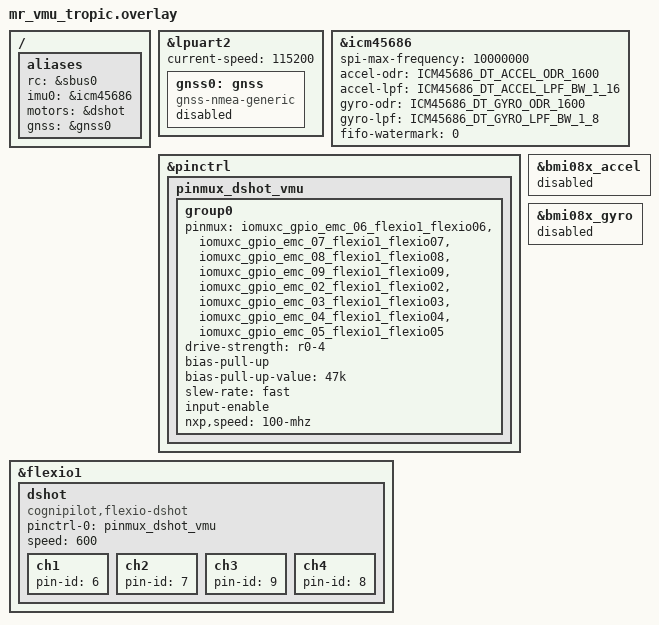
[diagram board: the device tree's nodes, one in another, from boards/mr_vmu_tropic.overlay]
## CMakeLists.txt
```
cmake_minimum_required(VERSION 3.20.0)

list(APPEND DTS_ROOT ${CMAKE_CURRENT_SOURCE_DIR})

get_filename_component(REPO_ROOT ${CMAKE_CURRENT_SOURCE_DIR} DIRECTORY)
get_filename_component(WORKSPACE_ROOT ${REPO_ROOT} DIRECTORY)
set(ZEPHYR_MODULES
  ${WORKSPACE_ROOT}/modules/hal/cmsis
  ${WORKSPACE_ROOT}/modules/hal/cmsis_6
  ${WORKSPACE_ROOT}/modules/hal/nxp
  ${WORKSPACE_ROOT}/modules/lib/cmsis-dsp
  ${WORKSPACE_ROOT}/modules/lib/zenoh-pico
  ${WORKSPACE_ROOT}/modules/lib/zros
  ${WORKSPACE_ROOT}/modules/lib/zephyr_boards
)

find_package(Zephyr REQUIRED HINTS $ENV{ZEPHYR_BASE})
project(rdd2 LANGUAGES C)

set(RDD2_FLATBUFFER_SCHEMA_DIR
  ${WORKSPACE_ROOT}/modules/lib/synapse_msgs_fbs/fbs/synapse
)
set(RDD2_FLATBUFFER_SCHEMA
  ${RDD2_FLATBUFFER_SCHEMA_DIR}/synapse_topics.fbs
)
set(RDD2_FLATBUFFER_LOG_SCHEMA
  ${RDD2_FLATBUFFER_SCHEMA_DIR}/synapse_log.fbs
)
set(RDD2_FLATBUFFER_SIL_SCHEMA
  ${RDD2_FLATBUFFER_SCHEMA_DIR}/synapse_sil.fbs
)
set(RDD2_FLATBUFFER_GENERATED_DIR
  ${CMAKE_CURRENT_BINARY_DIR}/generated/flatbuffers
)
set(RDD2_FLATBUFFER_STAMP
  ${RDD2_FLATBUFFER_GENERATED_DIR}/.flatcc.stamp
)
set(RDD2_FLATBUFFER_BFBS_STAMP
  ${RDD2_FLATBUFFER_GENERATED_DIR}/.bfbs.stamp
)
set(RDD2_FLATBUFFER_STAGE_STAMP
  ${RDD2_FLATBUFFER_GENERATED_DIR}/.schema-copy.stamp
)
option(RDD2_FLATBUFFER_CODEGEN
  "Generate FlatBuffer C headers and binary schemas into the build tree when flatcc is available"
  ON
)

find_program(RDD2_FLATCC_EXECUTABLE NAMES flatcc)

if(RDD2_FLATCC_EXECUTABLE)
  get_filename_component(RDD2_FLATCC_REALPATH ${RDD2_FLATCC_EXECUTABLE} REALPATH)
  get_filename_component(RDD2_FLATCC_BIN_DIR ${RDD2_FLATCC_REALPATH} DIRECTORY)
  get_filename_component(RDD2_FLATCC_PREFIX ${RDD2_FLATCC_BIN_DIR} DIRECTORY)
endif()

find_path(RDD2_FLATCC_INCLUDE_DIR
  NAMES flatcc/flatcc_builder.h
  HINTS ${RDD2_FLATCC_PREFIX}/include
)

if(NOT EXISTS ${RDD2_FLATBUFFER_SCHEMA})
  message(FATAL_ERROR
    "Missing FlatBuffer topic schema: ${RDD2_FLATBUFFER_SCHEMA}. "
    "Run west update to fetch modules/lib/synapse_msgs_fbs."
  )
endif()

if(NOT EXISTS ${RDD2_FLATBUFFER_LOG_SCHEMA})
  message(FATAL_ERROR
    "Missing FlatBuffer log schema: ${RDD2_FLATBUFFER_LOG_SCHEMA}. "
    "Run west update to fetch modules/lib/synapse_msgs_fbs."
  )
endif()

if(NOT EXISTS ${RDD2_FLATBUFFER_SIL_SCHEMA})
  message(FATAL_ERROR
    "Missing FlatBuffer SITL schema: ${RDD2_FLATBUFFER_SIL_SCHEMA}. "
    "Run west update to fetch modules/lib/synapse_msgs_fbs."
  )
endif()

if(RDD2_FLATBUFFER_CODEGEN AND RDD2_FLATCC_EXECUTABLE)
  add_custom_command(
    OUTPUT ${RDD2_FLATBUFFER_STAGE_STAMP}
    COMMAND ${CMAKE_COMMAND} -E make_directory ${RDD2_FLATBUFFER_GENERATED_DIR}
    COMMAND ${CMAKE_COMMAND} -E copy_if_different
            ${RDD2_FLATBUFFER_SCHEMA}
            ${RDD2_FLATBUFFER_GENERATED_DIR}/synapse_topics.fbs
    COMMAND ${CMAKE_COMMAND} -E copy_if_different
            ${RDD2_FLATBUFFER_LOG_SCHEMA}
            ${RDD2_FLATBUFFER_GENERATED_DIR}/synapse_log.fbs
    COMMAND ${CMAKE_COMMAND} -E copy_if_different
            ${RDD2_FLATBUFFER_SIL_SCHEMA}
            ${RDD2_FLATBUFFER_GENERATED_DIR}/synapse_sil.fbs
    COMMAND ${CMAKE_COMMAND} -E touch ${RDD2_FLATBUFFER_STAGE_STAMP}
    DEPENDS
      ${RDD2_FLATBUFFER_SCHEMA}
      ${RDD2_FLATBUFFER_LOG_SCHEMA}
      ${RDD2_FLATBUFFER_SIL_SCHEMA}
    COMMENT "Staging FlatBuffer schemas into ${RDD2_FLATBUFFER_GENERATED_DIR}"
    VERBATIM
  )

  add_custom_command(
    OUTPUT ${RDD2_FLATBUFFER_STAMP}
    COMMAND ${RDD2_FLATCC_EXECUTABLE}
            -a
            -I${RDD2_FLATBUFFER_SCHEMA_DIR}
            -o${RDD2_FLATBUFFER_GENERATED_DIR}
            ${RDD2_FLATBUFFER_SCHEMA}
    COMMAND ${RDD2_FLATCC_EXECUTABLE}
            -a
            -I${RDD2_FLATBUFFER_SCHEMA_DIR}
            -o${RDD2_FLATBUFFER_GENERATED_DIR}
            ${RDD2_FLATBUFFER_LOG_SCHEMA}
    COMMAND ${RDD2_FLATCC_EXECUTABLE}
            -a
            -I${RDD2_FLATBUFFER_SCHEMA_DIR}
            -o${RDD2_FLATBUFFER_GENERATED_DIR}
            ${RDD2_FLATBUFFER_SIL_SCHEMA}
    COMMAND ${CMAKE_COMMAND} -E touch ${RDD2_FLATBUFFER_STAMP}
    DEPENDS
      ${RDD2_FLATBUFFER_STAGE_STAMP}
      ${RDD2_FLATBUFFER_SCHEMA}
      ${RDD2_FLATBUFFER_LOG_SCHEMA}
      ${RDD2_FLATBUFFER_SIL_SCHEMA}
    COMMENT "Generating FlatBuffer headers into ${RDD2_FLATBUFFER_GENERATED_DIR}"
    VERBATIM
  )

  add_custom_target(rdd2_flatbuffer_codegen DEPENDS ${RDD2_FLATBUFFER_STAMP})
  add_custom_command(
    OUTPUT ${RDD2_FLATBUFFER_BFBS_STAMP}
    COMMAND ${RDD2_FLATCC_EXECUTABLE}
            --schema
            -I${RDD2_FLATBUFFER_SCHEMA_DIR}
            -o${RDD2_FLATBUFFER_GENERATED_DIR}
            ${RDD2_FLATBUFFER_SCHEMA}
    COMMAND ${RDD2_FLATCC_EXECUTABLE}
            --schema
            -I${RDD2_FLATBUFFER_SCHEMA_DIR}
            -o${RDD2_FLATBUFFER_GENERATED_DIR}
            ${RDD2_FLATBUFFER_LOG_SCHEMA}
    COMMAND ${RDD2_FLATCC_EXECUTABLE}
            --schema
            -I${RDD2_FLATBUFFER_SCHEMA_DIR}
            -o${RDD2_FLATBUFFER_GENERATED_DIR}
            ${RDD2_FLATBUFFER_SIL_SCHEMA}
    COMMAND ${CMAKE_COMMAND} -E touch ${RDD2_FLATBUFFER_BFBS_STAMP}
    DEPENDS
      ${RDD2_FLATBUFFER_STAGE_STAMP}
      ${RDD2_FLATBUFFER_SCHEMA}
      ${RDD2_FLATBUFFER_LOG_SCHEMA}
      ${RDD2_FLATBUFFER_SIL_SCHEMA}
    COMMENT "Generating FlatBuffer binary schemas into ${RDD2_FLATBUFFER_GENERATED_DIR}"
    VERBATIM
  )

  add_custom_target(rdd2_flatbuffer_schema_codegen
    DEPENDS ${RDD2_FLATBUFFER_BFBS_STAMP}
  )
elseif(RDD2_FLATBUFFER_CODEGEN)
  message(FATAL_ERROR
    "flatcc is required to build RDD2 because the firmware now compiles "
    "against generated FlatBuffer headers."
  )
endif()

if(NOT RDD2_FLATCC_INCLUDE_DIR)
  message(FATAL_ERROR
    "Missing flatcc headers. Expected flatcc/flatcc_builder.h near ${RDD2_FLATCC_EXECUTABLE}."
  )
endif()

if(TARGET rdd2_flatbuffer_codegen)
  add_dependencies(app rdd2_flatbuffer_codegen)
endif()

if(TARGET rdd2_flatbuffer_schema_codegen)
  add_dependencies(app rdd2_flatbuffer_schema_codegen)
endif()

target_include_directories(app PRIVATE
  include
  ${RDD2_FLATBUFFER_GENERATED_DIR}
  ${RDD2_FLATCC_INCLUDE_DIR}
  ${ZEPHYR_BASE}/../modules/hal/nxp/mcux/mcux-sdk-ng/drivers/flexio
)

add_subdirectory(src)
add_subdirectory(subsys)
add_subdirectory(drivers)
```

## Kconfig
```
source "Kconfig.zephyr"

menu "RDD2"

rsource "subsys/Kconfig"
rsource "drivers/Kconfig"

endmenu
```

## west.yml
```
# SPDX-License-Identifier: Apache-2.0

manifest:
  self:
    path: cerebri/rdd2
    west-commands: rdd2/scripts/west-commands.yml

  remotes:
    - name: zephyrproject-rtos
      url-base: https://github.com/zephyrproject-rtos
    - name: cognipilot
      url-base: https://github.com/CogniPilot

  projects:
    - name: zephyr
      remote: cognipilot
      revision: c908d12ebc2baa679d0f5b8e31eeb459ea93caff # cerebri2 4/14/26
      path: zephyr
      west-commands: scripts/west-commands.yml
    - name: cmsis
      remote: zephyrproject-rtos
      revision: 512cc7e895e8491696b61f7ba8066b4a182569b8 # loaded in ~/cognipilot/ws/modules/hal/cmsis
      path: modules/hal/cmsis
    - name: cmsis-dsp
      remote: zephyrproject-rtos
      revision: 97512610ec92058f0119450b9e743eeb7e95b5c8 # loaded in ~/cognipilot/ws/modules/lib/cmsis-dsp
      path: modules/lib/cmsis-dsp
    - name: cmsis_6
      remote: zephyrproject-rtos
      revision: 30a859f44ef8ab4dc8f84b03ed586fd16ccf9d74 # loaded in ~/cognipilot/ws/modules/hal/cmsis_6
      path: modules/hal/cmsis_6
    - name: hal_nxp
      remote: cognipilot
      revision: cf8f1631e862528ee044850bcc70273975b90771 # loaded in ~/cognipilot/ws/modules/hal/nxp
      path: modules/hal/nxp
    - name: zros
      remote: cognipilot
      revision: 959bce412d6e12b3a49fb8b55c219affcf7f6d0e # cerebri2 4/14/26
      path: modules/lib/zros
    - name: zenoh-pico
      url: https://github.com/cognipilot/zenoh-pico.git
      revision: 3c203551f37c5ad0b6f5471a8c344d376c04127b  # cerebri2 4/14/26
      path: modules/lib/zenoh-pico
    - name: zephyr_boards
      remote: cognipilot
      revision: d006ec84e621ee33f43c233a96380c8c3f6470eb # cerebri2 4/14/26
      path: modules/lib/zephyr_boards
    - name: synapse_msgs_fbs
      url: https://github.com/CogniPilot/synapse_msgs_fbs.git
      revision: 764acec47c44f8b9363e2a704cb4b8043b127d88 # cerebri2 4/14/26
      path: modules/lib/synapse_msgs_fbs
```

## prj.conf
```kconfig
CONFIG_MAIN_STACK_SIZE=6144
CONFIG_MAIN_THREAD_PRIORITY=2
CONFIG_SYSTEM_WORKQUEUE_STACK_SIZE=2048
CONFIG_THREAD_NAME=y
CONFIG_THREAD_MONITOR=y
CONFIG_THREAD_STACK_INFO=y
CONFIG_INIT_STACKS=y
CONFIG_THREAD_RUNTIME_STATS=y

CONFIG_ASSERT=y
CONFIG_FPU=y
CONFIG_POLL=y
CONFIG_HEAP_MEM_POOL_SIZE=32768
CONFIG_ZROS=y
CONFIG_ZROS_SHELL=y

CONFIG_LOG=y
CONFIG_LOG_MODE_IMMEDIATE=y
CONFIG_LOG_DEFAULT_LEVEL=2
CONFIG_LOG_CMDS=y
CONFIG_LOG_BACKEND_UART=n
CONFIG_LOG_PRINTK=n

CONFIG_CONSOLE=y
CONFIG_SERIAL=y
CONFIG_UART_ASYNC_API=y
CONFIG_UART_INTERRUPT_DRIVEN=y

CONFIG_SHELL=y
CONFIG_SHELL_BACKEND_SERIAL=y
CONFIG_SHELL_LOG_BACKEND=y
CONFIG_SHELL_PROMPT_UART="rdd2:~$ "
CONFIG_SHELL_STACK_SIZE=6144
CONFIG_DEVICE_SHELL=y
CONFIG_KERNEL_SHELL=y
```

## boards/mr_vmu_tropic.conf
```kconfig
CONFIG_INPUT=y
CONFIG_INPUT_MODE_SYNCHRONOUS=y
CONFIG_INPUT_SHELL=y
CONFIG_INPUT_EVENT_DUMP=y
CONFIG_INPUT_CRSF=y
CONFIG_INPUT_CRSF_SEND_SYNC=y
CONFIG_INPUT_CRSF_REPORT_FILTER=1
CONFIG_INPUT_CRSF_THREAD_PRIORITY=1
CONFIG_INPUT_CRSF_THREAD_STACK_SIZE=2048
CONFIG_INPUT_CRSF_USE_DTCM_FOR_DMA_BUFFER=y
CONFIG_CODE_DATA_RELOCATION=y
CONFIG_POSIX_API=y
CONFIG_MAX_PTHREAD_MUTEX_COUNT=16
CONFIG_MAX_PTHREAD_COND_COUNT=8

CONFIG_DSP=y
CONFIG_DSP_BACKEND_CMSIS=y
CONFIG_CMSIS_DSP=y

CONFIG_SENSOR=y
CONFIG_SENSOR_ASYNC_API=y
CONFIG_SENSOR_SHELL=y
CONFIG_ICM45686_STREAM=y
CONFIG_PINCTRL=y
CONFIG_CLOCK_CONTROL=y
CONFIG_DMA=y
CONFIG_MDIO=y
CONFIG_MDIO_SHELL=y
CONFIG_NETWORKING=y
CONFIG_NET_IPV4=y
CONFIG_NET_IPV6=n
CONFIG_NET_UDP=y
CONFIG_NET_CONFIG_SETTINGS=y
CONFIG_NET_CONFIG_NEED_IPV4=y
CONFIG_NET_CONFIG_INIT_TIMEOUT=0
CONFIG_NET_CONFIG_MY_IPV4_ADDR="192.0.2.1"
CONFIG_NET_CONFIG_MY_IPV4_NETMASK="255.255.255.0"
CONFIG_NET_CONFIG_PEER_IPV4_ADDR="192.0.2.2"
CONFIG_NET_SHELL=y
CONFIG_NET_STATISTICS=y
CONFIG_NET_STATISTICS_PER_INTERFACE=y
CONFIG_NET_STATISTICS_USER_API=y
CONFIG_NET_STATISTICS_IPV4=y
CONFIG_NET_STATISTICS_ICMP=y
CONFIG_NET_STATISTICS_UDP=y
CONFIG_NET_STATISTICS_ETHERNET=y
CONFIG_ZENOH_PICO_SHELL=y
CONFIG_ZENOH_PICO_SHELL_MODE="client"
CONFIG_ZENOH_PICO_SHELL_CONNECT_LOCATOR="udp/192.0.2.2:7447"
CONFIG_ZENOH_PICO_SHELL_SUB_KEYEXPR="**"
CONFIG_ZENOH_PICO_SHELL_THREAD_PRIORITY=5
CONFIG_ZENOH_PICO_SHELL_THREAD_STACK_SIZE=4096
CONFIG_ZENOH_PICO_SHELL_RETRY_MS=1000
CONFIG_ZENOH_PICO_SHELL_MAX_PAYLOAD=512
CONFIG_ZENOH_PICO_SHELL_MAX_KEYEXPR=96
CONFIG_SPI_NXP_LPSPI_DMA=n
CONFIG_GNSS=y
```

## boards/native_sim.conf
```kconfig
CONFIG_NATIVE_SIM_SLOWDOWN_TO_REAL_TIME=y
CONFIG_REQUIRES_FULL_LIBC=y

CONFIG_INPUT=y
CONFIG_INPUT_MODE_SYNCHRONOUS=y
CONFIG_SENSOR=y

CONFIG_UART_NATIVE_PTY=y
CONFIG_UART_NATIVE_PTY_0_ON_STDINOUT=y
```

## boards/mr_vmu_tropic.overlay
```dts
/* SPDX-License-Identifier: Apache-2.0 */

#include <zephyr/dt-bindings/sensor/icm45686.h>

/ {
	aliases {
		rc = &sbus0;
		imu0 = &icm45686;
		motors = &dshot;
		gnss = &gnss0;
	};
};

&lpuart2 {
	status = "okay";
	current-speed = <115200>;

	gnss0: gnss {
		status = "disabled";
		compatible = "gnss-nmea-generic";
	};
};

&icm45686 {
	spi-max-frequency = <10000000>;
	/*
	 * Pace the rate loop directly from the IMU data-ready interrupt at
	 * 1600 Hz. Keep the filter settings conservative enough to cut motor
	 * vibration without adding extra control-path threading.
	 */
	accel-odr = <ICM45686_DT_ACCEL_ODR_1600>;
	accel-lpf = <ICM45686_DT_ACCEL_LPF_BW_1_16>;
	gyro-odr = <ICM45686_DT_GYRO_ODR_1600>;
	gyro-lpf = <ICM45686_DT_GYRO_LPF_BW_1_8>;
	fifo-watermark = <0>;
};

&pinctrl {
	pinmux_dshot_vmu: pinmux_dshot_vmu {
		group0 {
			pinmux = <&iomuxc_gpio_emc_06_flexio1_flexio06>,
				 <&iomuxc_gpio_emc_07_flexio1_flexio07>,
				 <&iomuxc_gpio_emc_08_flexio1_flexio08>,
				 <&iomuxc_gpio_emc_09_flexio1_flexio09>,
				 <&iomuxc_gpio_emc_02_flexio1_flexio02>,
				 <&iomuxc_gpio_emc_03_flexio1_flexio03>,
				 <&iomuxc_gpio_emc_04_flexio1_flexio04>,
				 <&iomuxc_gpio_emc_05_flexio1_flexio05>;
			drive-strength = "r0-4";
			bias-pull-up;
			bias-pull-up-value = "47k";
			slew-rate = "fast";
			input-enable;
			nxp,speed = "100-mhz";
		};
	};
};

&flexio1 {
	status = "okay";

	dshot: dshot {
		compatible = "cognipilot,flexio-dshot";
		pinctrl-0 = <&pinmux_dshot_vmu>;
		pinctrl-names = "default";
		status = "okay";
		speed = <600>;

		ch1 {
			pin-id = <6>;
		};

		ch2 {
			pin-id = <7>;
		};

		ch3 {
			pin-id = <9>;
		};

		ch4 {
			pin-id = <8>;
		};
	};
};

&bmi08x_accel {
	status = "disabled";
};

&bmi08x_gyro {
	status = "disabled";
};
```

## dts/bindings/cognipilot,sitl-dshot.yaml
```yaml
# SPDX-License-Identifier: Apache-2.0

description: RDD2 native_sim DSHOT output device

compatible: "cognipilot,sitl-dshot"

include: sensor-device.yaml

properties:
  channel-count:
    type: int
    required: true
    description: Number of simulated motor output channels.
```

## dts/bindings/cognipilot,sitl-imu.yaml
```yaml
# SPDX-License-Identifier: Apache-2.0

description: RDD2 native_sim IMU sensor device

compatible: "cognipilot,sitl-imu"

include: sensor-device.yaml
```

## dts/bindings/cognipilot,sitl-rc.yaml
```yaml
# SPDX-License-Identifier: Apache-2.0

description: RDD2 native_sim RC input device

compatible: "cognipilot,sitl-rc"

include: base.yaml
```

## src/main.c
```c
/*
 * SPDX-License-Identifier: Apache-2.0
 */

#include "attitude_control.h"
#include "attitude_estimator.h"
#include "control_io.h"
#include "flight_mode.h"
#include "hotpath_memory.h"
#include "imu_latency_stats.h"
#include "motor_output.h"
#include "rate_control.h"
#include "topic_bus.h"

#include <stdbool.h>
#include <stdint.h>

#include <zephyr/kernel.h>
#include <zephyr/logging/log.h>

#include <zros/zros_node.h>
#include <zros/zros_pub.h>

LOG_MODULE_REGISTER(rdd2, LOG_LEVEL_INF);

struct control_context {
	synapse_topic_Vec3f_t gyro;
	synapse_topic_Vec3f_t accel;
	synapse_topic_RcChannels16_t rc;
	synapse_topic_ControlStatus_t status;
	synapse_topic_AttitudeEuler_t attitude;
	synapse_topic_AttitudeEuler_t attitude_desired;
	synapse_topic_RateTriplet_t rate_desired;
	synapse_topic_RateTriplet_t rate_cmd;
	synapse_topic_MotorValues4f_t motors;
	synapse_topic_MotorRaw4u16_t raw_test;
	float throttle_input;
	float throttle_cmd;
	float dt;
	uint32_t imu_to_motor_latency_us;
	int64_t now_ms;
	bool rc_stale;
	enum rdd2_flight_mode flight_mode;
};

/* Keep the persistent 1600 Hz rate-loop working set in DTCM on Tropic. */
static RDD2_HOTPATH_DTCM_BSS struct rdd2_attitude_controller g_attitude_controller;
static RDD2_HOTPATH_DTCM_BSS struct rdd2_attitude_estimator g_attitude_estimator;
static RDD2_HOTPATH_DTCM_BSS struct rdd2_rate_controller g_rate_controller;
static RDD2_HOTPATH_DTCM_BSS struct control_context g_control_ctx;
static struct zros_node g_rdd2_main_node;
static struct zros_pub g_rdd2_flight_state_pub;
static RDD2_HOTPATH_DTCM_BSS rdd2_topic_flight_state_blob_t g_rdd2_flight_state_blob;

static bool loop_divider_expired(uint32_t *countdown, uint32_t divisor)
{
	if (*countdown > 0U) {
		(*countdown)--;
		return false;
	}

	*countdown = divisor - 1U;
	return true;
}

static bool attitude_update_due(enum rdd2_flight_mode mode, bool armed,
				uint32_t *autolevel_countdown, uint32_t *background_countdown)
{
	if (armed && mode == RDD2_FLIGHT_MODE_AUTO_LEVEL) {
		return loop_divider_expired(autolevel_countdown, RDD2_ATTITUDE_AUTOLEVEL_DIV);
	}

	return loop_divider_expired(background_countdown, RDD2_ATTITUDE_BACKGROUND_DIV);
}

static int flight_state_topic_init(void)
{
	zros_node_init(&g_rdd2_main_node, "rdd2_main");
	return zros_pub_init(&g_rdd2_flight_state_pub, &g_rdd2_main_node, &topic_flight_state,
			     &g_rdd2_flight_state_blob);
}

static void publish_flight_state(const struct control_context *ctx)
{
	static uint32_t publish_countdown;
	size_t len;

	if (!loop_divider_expired(&publish_countdown, RDD2_FLIGHT_STATE_PUBLISH_DIV)) {
		return;
	}

	len = rdd2_topic_fb_pack_flight_state(
		g_rdd2_flight_state_blob, sizeof(g_rdd2_flight_state_blob), &ctx->gyro, &ctx->accel,
		&ctx->rc, &ctx->status, &ctx->attitude, &ctx->attitude_desired, &ctx->rate_desired,
		&ctx->rate_cmd, ctx->imu_to_motor_latency_us);
	if (len != sizeof(g_rdd2_flight_state_blob)) {
		return;
	}

	(void)zros_pub_update(&g_rdd2_flight_state_pub);
}

static uint32_t imu_to_motor_latency_us(uint64_t imu_interrupt_timestamp_ns,
					uint64_t motor_signal_timestamp_ns)
{
	uint64_t latency_ns;

	if (imu_interrupt_timestamp_ns == 0U || motor_signal_timestamp_ns == 0U ||
	    motor_signal_timestamp_ns <= imu_interrupt_timestamp_ns) {
		return 0U;
	}

	latency_ns = motor_signal_timestamp_ns - imu_interrupt_timestamp_ns;
	if (latency_ns >= ((uint64_t)UINT32_MAX * 1000U)) {
		return UINT32_MAX;
	}

	return (uint32_t)(latency_ns / 1000U);
}

static void finalize_cycle(struct control_context *ctx, uint64_t imu_interrupt_timestamp_ns,
			   uint64_t motor_signal_timestamp_ns)
{
	ctx->imu_to_motor_latency_us =
		imu_to_motor_latency_us(imu_interrupt_timestamp_ns, motor_signal_timestamp_ns);
	rdd2_imu_latency_stats_update(ctx->imu_to_motor_latency_us);
	publish_flight_state(ctx);
}

int main(void)
{
	struct control_context *const ctx = &g_control_ctx;
	enum rdd2_flight_mode previous_mode = RDD2_FLIGHT_MODE_ACRO;
	bool was_armed = false;
	uint32_t autolevel_attitude_countdown = 0U;
	uint32_t background_attitude_countdown = 0U;
	synapse_topic_Vec3f_t attitude_gyro_accum = {0};
	synapse_topic_Vec3f_t attitude_accel_accum = {0};
	float attitude_dt_accum = 0.0f;
	uint32_t attitude_sample_count = 0U;
	int rc;

	*ctx = (struct control_context){0};
	rdd2_attitude_controller_init(&g_attitude_controller);
	rdd2_attitude_estimator_init(&g_attitude_estimator);
	rdd2_rate_controller_init(&g_rate_controller);
	rdd2_imu_latency_stats_reset();

	rc = flight_state_topic_init();
	if (rc != 0) {
		return rc;
	}

	rdd2_motor_output_init();

	rc = rdd2_control_io_init();
	if (rc != 0) {
		return rc;
	}

	LOG_INF("RDD2 flight stack starting");

	while (true) {
		bool run_attitude_update;
		bool controller_reset_required;
		float attitude_dt = 0.0f;
		uint64_t imu_interrupt_timestamp_ns = 0U;
		uint64_t motor_signal_timestamp_ns = 0U;

		was_armed = ctx->status.armed;
		previous_mode = ctx->flight_mode;

		rdd2_control_input_wait(&ctx->gyro, &ctx->accel, &ctx->rc, &ctx->status, &ctx->dt,
					&imu_interrupt_timestamp_ns);
		ctx->now_ms = k_uptime_get();
		ctx->rc_stale = !ctx->status.rc_valid || ((ctx->now_ms - ctx->status.rc_stamp_ms) >
							  RDD2_RC_STALE_TIMEOUT_MS);
		ctx->flight_mode = rdd2_flight_mode_from_rc(&ctx->rc);
		ctx->status.flight_mode = (uint8_t)ctx->flight_mode;

		if (ctx->dt <= 0.0f) {
			ctx->dt = RDD2_CONTROL_DT_S;
		}

		ctx->status.arm_switch = rdd2_rate_arm_switch_high(&ctx->rc);
		ctx->status.throttle_us = rdd2_rate_throttle_us(&ctx->rc);
		ctx->status.rc_stale = ctx->rc_stale;
		ctx->rate_cmd = (synapse_topic_RateTriplet_t){0};
		ctx->motors = (synapse_topic_MotorValues4f_t){0};
		ctx->imu_to_motor_latency_us = 0U;

		if (!ctx->status.imu_ok || ctx->rc_stale || !ctx->status.arm_switch) {
			ctx->status.armed = false;
		} else if (!ctx->status.armed && ctx->status.throttle_us <= RDD2_THROTTLE_ARM_MAX) {
			ctx->status.armed = true;
		}

		run_attitude_update = attitude_update_due(ctx->flight_mode, ctx->status.armed,
							  &autolevel_attitude_countdown,
							  &background_attitude_countdown);
		controller_reset_required =
			!ctx->status.armed || !was_armed || ctx->flight_mode != previous_mode;

		if (ctx->status.imu_ok) {
			attitude_gyro_accum.x += ctx->gyro.x;
			attitude_gyro_accum.y += ctx->gyro.y;
			attitude_gyro_accum.z += ctx->gyro.z;
			attitude_accel_accum.x += ctx->accel.x;
			attitude_accel_accum.y += ctx->accel.y;
			attitude_accel_accum.z += ctx->accel.z;
			attitude_dt_accum += ctx->dt;
			attitude_sample_count++;
		} else {
			attitude_gyro_accum = (synapse_topic_Vec3f_t){0};
			attitude_accel_accum = (synapse_topic_Vec3f_t){0};
			attitude_dt_accum = 0.0f;
			attitude_sample_count = 0U;
			ctx->attitude = (synapse_topic_AttitudeEuler_t){0};
			ctx->attitude_desired = (synapse_topic_AttitudeEuler_t){0};
			ctx->rate_desired = (synapse_topic_RateTriplet_t){0};
		}

		if (!ctx->status.armed) {
			if (ctx->status.imu_ok && run_attitude_update) {
				rdd2_attitude_estimator_reset_from_accel(&g_attitude_estimator,
									 &ctx->accel);
				rdd2_attitude_estimator_get_attitude(&g_attitude_estimator,
								     &ctx->attitude);
				ctx->attitude_desired = ctx->attitude;
				attitude_gyro_accum = (synapse_topic_Vec3f_t){0};
				attitude_accel_accum = (synapse_topic_Vec3f_t){0};
				attitude_dt_accum = 0.0f;
				attitude_sample_count = 0U;
			}
		} else if (ctx->status.imu_ok && run_attitude_update &&
			   attitude_sample_count > 0U) {
			float sample_scale = 1.0f / (float)attitude_sample_count;
			synapse_topic_Vec3f_t avg_gyro = {
				.x = attitude_gyro_accum.x * sample_scale,
				.y = attitude_gyro_accum.y * sample_scale,
				.z = attitude_gyro_accum.z * sample_scale,
			};
			synapse_topic_Vec3f_t avg_accel = {
				.x = attitude_accel_accum.x * sample_scale,
				.y = attitude_accel_accum.y * sample_scale,
				.z = attitude_accel_accum.z * sample_scale,
			};

			attitude_dt = attitude_dt_accum;
			rdd2_attitude_estimator_predict(&g_attitude_estimator, &avg_gyro,
							&avg_accel, attitude_dt);
			rdd2_attitude_estimator_get_attitude(&g_attitude_estimator, &ctx->attitude);
			attitude_gyro_accum = (synapse_topic_Vec3f_t){0};
			attitude_accel_accum = (synapse_topic_Vec3f_t){0};
			attitude_dt_accum = 0.0f;
			attitude_sample_count = 0U;
		}

		if (controller_reset_required) {
			rdd2_attitude_controller_reset(&g_attitude_controller);
			rdd2_rate_controller_reset(&g_rate_controller);
		}

		if (rdd2_motor_test_get(&ctx->motors)) {
			motor_signal_timestamp_ns =
				rdd2_motor_output_write_all(&ctx->motors, true, true);
			finalize_cycle(ctx, imu_interrupt_timestamp_ns, motor_signal_timestamp_ns);
			continue;
		}

		if (rdd2_motor_raw_test_get(&ctx->raw_test)) {
			motor_signal_timestamp_ns =
				rdd2_motor_output_write_all_raw(&ctx->raw_test, true);
			finalize_cycle(ctx, imu_interrupt_timestamp_ns, motor_signal_timestamp_ns);
			continue;
		}

		if (!ctx->status.imu_ok || ctx->rc_stale) {
			motor_signal_timestamp_ns =
				rdd2_motor_output_write_all(&ctx->motors, false, false);
			finalize_cycle(ctx, imu_interrupt_timestamp_ns, motor_signal_timestamp_ns);
			continue;
		}

		switch (ctx->flight_mode) {
		case RDD2_FLIGHT_MODE_AUTO_LEVEL:
			if (ctx->status.imu_ok && (controller_reset_required ||
						   (run_attitude_update && attitude_dt > 0.0f))) {
				rdd2_attitude_desired_from_rc(&ctx->rc, &ctx->attitude,
							      &ctx->attitude_desired);
				rdd2_attitude_controller_step(
					&g_attitude_controller, &ctx->attitude,
					&ctx->attitude_desired, &ctx->rc,
					(attitude_dt > 0.0f) ? attitude_dt : ctx->dt,
					&ctx->rate_desired);
			}
			ctx->rate_desired.yaw = rdd2_rate_yaw_desired_from_rc(&ctx->rc);
			break;
		case RDD2_FLIGHT_MODE_ACRO:
		default:
			rdd2_rate_desired_from_rc(&ctx->rc, &ctx->rate_desired);
			ctx->attitude_desired = ctx->attitude;
			break;
		}

		ctx->throttle_input = rdd2_rate_throttle_input_from_rc(&ctx->rc);
		ctx->throttle_cmd =
			rdd2_rate_throttle_command(ctx->throttle_input, ctx->status.armed);
		rdd2_rate_controller_step(
			&g_rate_controller, &ctx->rate_desired, &ctx->gyro, ctx->dt,
			ctx->status.armed && ctx->throttle_input > RDD2_PID_INTEGRATE_THROTTLE_MIN,
			&ctx->rate_cmd);
		rdd2_mix_quad_x(ctx->throttle_cmd, &ctx->rate_cmd, &ctx->motors);
		motor_signal_timestamp_ns =
			rdd2_motor_output_write_all(&ctx->motors, ctx->status.armed, false);
		finalize_cycle(ctx, imu_interrupt_timestamp_ns, motor_signal_timestamp_ns);
	}

	return 0;
}
```

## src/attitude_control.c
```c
/*
 * SPDX-License-Identifier: Apache-2.0
 */

#include "attitude_control.h"

#include "rate_control.h"

#define RC_US_CENTER            1500
#define MAX_AUTO_LEVEL_TILT_RAD 0.61086524f
#define AUTO_LEVEL_ROLL_P_GAIN  4.0f
#define AUTO_LEVEL_PITCH_P_GAIN 4.0f

static float clampf(float value, float min_value, float max_value)
{
	if (value < min_value) {
		return min_value;
	}
	if (value > max_value) {
		return max_value;
	}
	return value;
}

static float rc_norm_centered(int32_t pulse_us)
{
	return clampf((float)(pulse_us - RC_US_CENTER) / 500.0f, -1.0f, 1.0f);
}

void rdd2_attitude_controller_init(struct rdd2_attitude_controller *controller)
{
	rdd2_pid_axis_init(&controller->roll);
	rdd2_pid_axis_init(&controller->pitch);

	controller->roll.kp = AUTO_LEVEL_ROLL_P_GAIN;
	controller->roll.ki = 0.0f;
	controller->roll.kd = 0.0f;
	controller->roll.i_limit = 0.0f;
	controller->roll.output_limit = RDD2_MAX_ROLL_PITCH_RATE_RAD_S;

	controller->pitch.kp = AUTO_LEVEL_PITCH_P_GAIN;
	controller->pitch.ki = 0.0f;
	controller->pitch.kd = 0.0f;
	controller->pitch.i_limit = 0.0f;
	controller->pitch.output_limit = RDD2_MAX_ROLL_PITCH_RATE_RAD_S;

	rdd2_attitude_controller_reset(controller);
}

void rdd2_attitude_controller_reset(struct rdd2_attitude_controller *controller)
{
	rdd2_pid_axis_reset(&controller->roll);
	rdd2_pid_axis_reset(&controller->pitch);
}

void rdd2_attitude_desired_from_rc(const synapse_topic_RcChannels16_t *rc,
				   const synapse_topic_AttitudeEuler_t *attitude,
				   synapse_topic_AttitudeEuler_t *attitude_desired)
{
	const int32_t *channels;

	if (rc == NULL || attitude == NULL || attitude_desired == NULL) {
		return;
	}

	channels = rdd2_topic_rc_channels_data_const(rc);
	attitude_desired->roll =
		rc_norm_centered(channels[RDD2_ROLL_CHANNEL_INDEX]) * MAX_AUTO_LEVEL_TILT_RAD;
	attitude_desired->pitch =
		rc_norm_centered(channels[RDD2_PITCH_CHANNEL_INDEX]) * MAX_AUTO_LEVEL_TILT_RAD;
	attitude_desired->yaw = attitude->yaw;
}

void rdd2_attitude_controller_step(struct rdd2_attitude_controller *controller,
				   const synapse_topic_AttitudeEuler_t *attitude,
				   const synapse_topic_AttitudeEuler_t *attitude_desired,
				   const synapse_topic_RcChannels16_t *rc, float dt,
				   synapse_topic_RateTriplet_t *rate_desired)
{
	const int32_t *channels;

	if (controller == NULL || attitude == NULL || attitude_desired == NULL || rc == NULL ||
	    rate_desired == NULL || dt <= 0.0f) {
		return;
	}

	controller->roll.setpoint = attitude_desired->roll;
	controller->roll.measurement = attitude->roll;
	rdd2_pid_axis_step(&controller->roll, dt, false);
	rate_desired->roll = clampf(controller->roll.u, -RDD2_MAX_ROLL_PITCH_RATE_RAD_S,
				    RDD2_MAX_ROLL_PITCH_RATE_RAD_S);

	controller->pitch.setpoint = attitude_desired->pitch;
	controller->pitch.measurement = attitude->pitch;
	rdd2_pid_axis_step(&controller->pitch, dt, false);
	rate_desired->pitch = clampf(controller->pitch.u, -RDD2_MAX_ROLL_PITCH_RATE_RAD_S,
				     RDD2_MAX_ROLL_PITCH_RATE_RAD_S);

	channels = rdd2_topic_rc_channels_data_const(rc);
	rate_desired->yaw =
		-rc_norm_centered(channels[RDD2_YAW_CHANNEL_INDEX]) * RDD2_MAX_YAW_RATE_RAD_S;
}
```

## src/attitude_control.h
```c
#ifndef RDD2_ATTITUDE_CONTROL_H_
#define RDD2_ATTITUDE_CONTROL_H_

#include "pid_axis.h"
#include "topic_flatbuffer.h"

struct rdd2_attitude_controller {
	struct rdd2_pid_axis roll;
	struct rdd2_pid_axis pitch;
};

void rdd2_attitude_controller_init(struct rdd2_attitude_controller *controller);
void rdd2_attitude_controller_reset(struct rdd2_attitude_controller *controller);
void rdd2_attitude_desired_from_rc(const synapse_topic_RcChannels16_t *rc,
				   const synapse_topic_AttitudeEuler_t *attitude,
				   synapse_topic_AttitudeEuler_t *attitude_desired);
void rdd2_attitude_controller_step(struct rdd2_attitude_controller *controller,
				   const synapse_topic_AttitudeEuler_t *attitude,
				   const synapse_topic_AttitudeEuler_t *attitude_desired,
				   const synapse_topic_RcChannels16_t *rc, float dt,
				   synapse_topic_RateTriplet_t *rate_desired);

#endif
```

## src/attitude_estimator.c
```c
/*
 * SPDX-License-Identifier: Apache-2.0
 */

#include "attitude_estimator.h"

#include <math.h>
#include <string.h>

#define RDD2_GRAVITY_M_S2           9.81f
#define RDD2_ATTITUDE_CORRECTION_KP 0.35f
#define RDD2_ATTITUDE_CORRECTION_KI 0.02f
#define RDD2_ATTITUDE_ACCEL_MIN_G   0.6f
#define RDD2_ATTITUDE_ACCEL_MAX_G   1.4f

static float clampf(float value, float min_value, float max_value)
{
	if (value < min_value) {
		return min_value;
	}
	if (value > max_value) {
		return max_value;
	}
	return value;
}

static void quaternion_normalize(struct rdd2_attitude_estimator *estimator)
{
	float norm_sq = (estimator->q_w * estimator->q_w) + (estimator->q_x * estimator->q_x) +
			(estimator->q_y * estimator->q_y) + (estimator->q_z * estimator->q_z);
	float inv_norm;

	if (norm_sq <= 1.0e-6f) {
		estimator->q_w = 1.0f;
		estimator->q_x = 0.0f;
		estimator->q_y = 0.0f;
		estimator->q_z = 0.0f;
		return;
	}

	inv_norm = 1.0f / sqrtf(norm_sq);
	estimator->q_w *= inv_norm;
	estimator->q_x *= inv_norm;
	estimator->q_y *= inv_norm;
	estimator->q_z *= inv_norm;
}

static void quaternion_from_euler(struct rdd2_attitude_estimator *estimator, float roll,
				  float pitch, float yaw)
{
	float cr = cosf(roll * 0.5f);
	float sr = sinf(roll * 0.5f);
	float cp = cosf(pitch * 0.5f);
	float sp = sinf(pitch * 0.5f);
	float cy = cosf(yaw * 0.5f);
	float sy = sinf(yaw * 0.5f);

	estimator->q_w = (cy * cp * cr) + (sy * sp * sr);
	estimator->q_x = (cy * cp * sr) - (sy * sp * cr);
	estimator->q_y = (sy * cp * sr) + (cy * sp * cr);
	estimator->q_z = (sy * cp * cr) - (cy * sp * sr);
	quaternion_normalize(estimator);
}

static void attitude_from_quaternion(const struct rdd2_attitude_estimator *estimator,
				     synapse_topic_AttitudeEuler_t *attitude)
{
	float sinr_cosp =
		(2.0f * estimator->q_w * estimator->q_x) + (2.0f * estimator->q_y * estimator->q_z);
	float cosr_cosp =
		1.0f -
		(2.0f * ((estimator->q_x * estimator->q_x) + (estimator->q_y * estimator->q_y)));
	float sinp =
		(2.0f * estimator->q_w * estimator->q_y) - (2.0f * estimator->q_z * estimator->q_x);
	float siny_cosp =
		(2.0f * estimator->q_w * estimator->q_z) + (2.0f * estimator->q_x * estimator->q_y);
	float cosy_cosp =
		1.0f -
		(2.0f * ((estimator->q_y * estimator->q_y) + (estimator->q_z * estimator->q_z)));

	attitude->roll = atan2f(sinr_cosp, cosr_cosp);
	attitude->pitch = asinf(clampf(sinp, -1.0f, 1.0f));
	attitude->yaw = atan2f(siny_cosp, cosy_cosp);
}

static bool accel_correction_valid(const synapse_topic_Vec3f_t *accel, float *ax, float *ay,
				   float *az)
{
	float accel_norm;

	accel_norm = sqrtf((accel->x * accel->x) + (accel->y * accel->y) + (accel->z * accel->z));
	if (accel_norm < (RDD2_ATTITUDE_ACCEL_MIN_G * RDD2_GRAVITY_M_S2) ||
	    accel_norm > (RDD2_ATTITUDE_ACCEL_MAX_G * RDD2_GRAVITY_M_S2)) {
		return false;
	}

	*ax = accel->x / accel_norm;
	*ay = accel->y / accel_norm;
	*az = accel->z / accel_norm;
	return true;
}

void rdd2_attitude_estimator_init(struct rdd2_attitude_estimator *estimator)
{
	if (estimator == NULL) {
		return;
	}

	memset(estimator, 0, sizeof(*estimator));
	estimator->q_w = 1.0f;
}

void rdd2_attitude_estimator_reset_from_accel(struct rdd2_attitude_estimator *estimator,
					      const synapse_topic_Vec3f_t *accel)
{
	float roll = 0.0f;
	float pitch = 0.0f;

	if (estimator == NULL) {
		return;
	}

	memset(estimator, 0, sizeof(*estimator));
	if (accel != NULL) {
		float yz_norm = sqrtf((accel->y * accel->y) + (accel->z * accel->z));

		roll = atan2f(accel->y, accel->z);
		pitch = atan2f(-accel->x, yz_norm);
	}

	quaternion_from_euler(estimator, roll, pitch, 0.0f);
}

void rdd2_attitude_estimator_predict(struct rdd2_attitude_estimator *estimator,
				     const synapse_topic_Vec3f_t *gyro,
				     const synapse_topic_Vec3f_t *accel, float dt)
{
	float gx;
	float gy;
	float gz;
	float q_w;
	float q_x;
	float q_y;
	float q_z;

	if (estimator == NULL || gyro == NULL || accel == NULL || dt <= 0.0f) {
		return;
	}

	gx = gyro->x;
	gy = gyro->y;
	gz = gyro->z;

	if (accel != NULL) {
		float ax;
		float ay;
		float az;

		if (accel_correction_valid(accel, &ax, &ay, &az)) {
			float gravity_x = 2.0f * ((estimator->q_x * estimator->q_z) -
						  (estimator->q_w * estimator->q_y));
			float gravity_y = 2.0f * ((estimator->q_w * estimator->q_x) +
						  (estimator->q_y * estimator->q_z));
			float gravity_z = (estimator->q_w * estimator->q_w) -
					  (estimator->q_x * estimator->q_x) -
					  (estimator->q_y * estimator->q_y) +
					  (estimator->q_z * estimator->q_z);
			float error_x = (ay * gravity_z) - (az * gravity_y);
			float error_y = (az * gravity_x) - (ax * gravity_z);
			float error_z = (ax * gravity_y) - (ay * gravity_x);

			estimator->gyro_bias_x += RDD2_ATTITUDE_CORRECTION_KI * error_x * dt;
			estimator->gyro_bias_y += RDD2_ATTITUDE_CORRECTION_KI * error_y * dt;
			estimator->gyro_bias_z += RDD2_ATTITUDE_CORRECTION_KI * error_z * dt;

			gx += estimator->gyro_bias_x + (RDD2_ATTITUDE_CORRECTION_KP * error_x);
			gy += estimator->gyro_bias_y + (RDD2_ATTITUDE_CORRECTION_KP * error_y);
			gz += estimator->gyro_bias_z + (RDD2_ATTITUDE_CORRECTION_KP * error_z);
		} else {
			gx += estimator->gyro_bias_x;
			gy += estimator->gyro_bias_y;
			gz += estimator->gyro_bias_z;
		}
	}

	q_w = estimator->q_w;
	q_x = estimator->q_x;
	q_y = estimator->q_y;
	q_z = estimator->q_z;

	estimator->q_w += 0.5f * (-q_x * gx - q_y * gy - q_z * gz) * dt;
	estimator->q_x += 0.5f * (q_w * gx + q_y * gz - q_z * gy) * dt;
	estimator->q_y += 0.5f * (q_w * gy - q_x * gz + q_z * gx) * dt;
	estimator->q_z += 0.5f * (q_w * gz + q_x * gy - q_y * gx) * dt;

	quaternion_normalize(estimator);
}

void rdd2_attitude_estimator_get_attitude(const struct rdd2_attitude_estimator *estimator,
					  synapse_topic_AttitudeEuler_t *attitude)
{
	if (estimator == NULL || attitude == NULL) {
		return;
	}

	attitude_from_quaternion(estimator, attitude);
}
```

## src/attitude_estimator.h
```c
#ifndef RDD2_ATTITUDE_ESTIMATOR_H_
#define RDD2_ATTITUDE_ESTIMATOR_H_

#include "topic_flatbuffer.h"

struct rdd2_attitude_estimator {
	float q_w;
	float q_x;
	float q_y;
	float q_z;
	float gyro_bias_x;
	float gyro_bias_y;
	float gyro_bias_z;
};

void rdd2_attitude_estimator_init(struct rdd2_attitude_estimator *estimator);
void rdd2_attitude_estimator_reset_from_accel(struct rdd2_attitude_estimator *estimator,
					      const synapse_topic_Vec3f_t *accel);
void rdd2_attitude_estimator_predict(struct rdd2_attitude_estimator *estimator,
				     const synapse_topic_Vec3f_t *gyro,
				     const synapse_topic_Vec3f_t *accel, float dt);
void rdd2_attitude_estimator_get_attitude(const struct rdd2_attitude_estimator *estimator,
					  synapse_topic_AttitudeEuler_t *attitude);

#endif
```

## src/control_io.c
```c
/*
 * SPDX-License-Identifier: Apache-2.0
 */

#include "control_io.h"

#include "imu_stream.h"
#include "rc_input.h"

#include <errno.h>

#include <zephyr/device.h>
#include <zephyr/drivers/misc/nxp_flexio_dshot/nxp_flexio_dshot.h>
#include <zephyr/kernel.h>
#include <zephyr/logging/log.h>

LOG_MODULE_DECLARE(rdd2, LOG_LEVEL_INF);

#define RC_NODE    DT_ALIAS(rc)
#define IMU_NODE   DT_ALIAS(imu0)
#define DSHOT_NODE DT_ALIAS(motors)
#define GNSS_NODE  DT_ALIAS(gnss)

static bool ready_or_log(const struct device *dev, const char *name)
{
	if (!device_is_ready(dev)) {
		LOG_ERR("%s not ready", name);
		return false;
	}

	return true;
}

int rdd2_control_io_init(void)
{
	const struct device *const rc_dev = DEVICE_DT_GET(RC_NODE);
	const struct device *const imu_dev = DEVICE_DT_GET(IMU_NODE);
	const struct device *const dshot_dev = DEVICE_DT_GET(DSHOT_NODE);
	const struct device *const gnss_dev = DEVICE_DT_GET_OR_NULL(GNSS_NODE);

	rdd2_rc_input_init();

	if (!ready_or_log(dshot_dev, "dshot")) {
		return -ENODEV;
	}

	ready_or_log(rc_dev, "rc");
	ready_or_log(imu_dev, "imu");

	if (gnss_dev != NULL && device_is_ready(gnss_dev)) {
		LOG_INF("gnss path ready");
	}

	if (nxp_flexio_dshot_channel_count(dshot_dev) != 4U) {
		LOG_ERR("expected 4 dshot channels");
		return -EINVAL;
	}

	return rdd2_imu_stream_init();
}

void rdd2_control_input_wait(synapse_topic_Vec3f_t *gyro, synapse_topic_Vec3f_t *accel,
			     synapse_topic_RcChannels16_t *rc,
			     synapse_topic_ControlStatus_t *status, float *dt,
			     uint64_t *imu_interrupt_timestamp_ns)
{
	bool rc_valid;

	status->imu_ok = rdd2_imu_stream_wait_next(gyro, accel, dt, imu_interrupt_timestamp_ns);
	status->rc_link_quality = rdd2_rc_input_link_quality_get(DEVICE_DT_GET(RC_NODE));
	rdd2_rc_input_latest_get(rc, &status->rc_stamp_ms, &rc_valid);
	status->rc_valid = rc_valid;
}
```

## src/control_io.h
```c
#ifndef RDD2_CONTROL_IO_H_
#define RDD2_CONTROL_IO_H_

#include "topic_flatbuffer.h"

int rdd2_control_io_init(void);
void rdd2_control_input_wait(synapse_topic_Vec3f_t *gyro, synapse_topic_Vec3f_t *accel,
			     synapse_topic_RcChannels16_t *rc,
			     synapse_topic_ControlStatus_t *status, float *dt,
			     uint64_t *imu_interrupt_timestamp_ns);

#endif
```

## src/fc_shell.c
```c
/*
 * SPDX-License-Identifier: Apache-2.0
 */

#include "flight_mode.h"
#include "imu_latency_stats.h"
#include "topic_bus.h"

#include <string.h>

#include <zephyr/kernel.h>
#include <zephyr/shell/shell.h>

#include <zros/zros_topic.h>

static void fc_print_latency_stats(const struct shell *sh)
{
	struct rdd2_imu_latency_stats_snapshot snapshot;

	if (!rdd2_imu_latency_stats_get(&snapshot)) {
		shell_print(sh, "latency us n=0");
		return;
	}

	shell_print(sh, "latency us last=%4lu mean=%7.2f std=%7.2f min=%4lu max=%4lu n=%llu",
		    (unsigned long)snapshot.last_us, (double)snapshot.mean_us,
		    (double)snapshot.stddev_us, (unsigned long)snapshot.min_us,
		    (unsigned long)snapshot.max_us, (unsigned long long)snapshot.sample_count);
}

static void fc_latest_rc(synapse_topic_RcChannels16_t *rc)
{
	memset(rc, 0, sizeof(*rc));

	if (!rdd2_topic_has_sample(&topic_rc)) {
		return;
	}

	(void)zros_topic_read(&topic_rc, rc);
}

static void fc_latest_state(synapse_topic_Vec3f_t *gyro, synapse_topic_Vec3f_t *accel,
			    synapse_topic_RcChannels16_t *rc, synapse_topic_ControlStatus_t *status,
			    synapse_topic_AttitudeEuler_t *attitude,
			    synapse_topic_AttitudeEuler_t *attitude_desired,
			    synapse_topic_RateTriplet_t *rate_desired,
			    synapse_topic_RateTriplet_t *rate_cmd, uint32_t *main_loop_latency_us)
{
	rdd2_topic_flight_state_blob_t blob = {0};

	memset(gyro, 0, sizeof(*gyro));
	memset(accel, 0, sizeof(*accel));
	memset(rc, 0, sizeof(*rc));
	memset(status, 0, sizeof(*status));
	memset(attitude, 0, sizeof(*attitude));
	memset(attitude_desired, 0, sizeof(*attitude_desired));
	memset(rate_desired, 0, sizeof(*rate_desired));
	memset(rate_cmd, 0, sizeof(*rate_cmd));
	if (main_loop_latency_us != NULL) {
		*main_loop_latency_us = 0U;
	}

	if (!rdd2_topic_has_sample(&topic_flight_state)) {
		return;
	}

	if (zros_topic_read(&topic_flight_state, &blob) != 0) {
		return;
	}

	(void)rdd2_topic_fb_unpack_flight_state(blob, sizeof(blob), gyro, accel, rc, status,
						attitude, attitude_desired, rate_desired, rate_cmd,
						main_loop_latency_us);
}

static int cmd_fc_status(const struct shell *sh, size_t argc, char **argv)
{
	synapse_topic_Vec3f_t gyro = {0};
	synapse_topic_Vec3f_t accel = {0};
	synapse_topic_RcChannels16_t rc = {0};
	synapse_topic_ControlStatus_t status = {0};
	synapse_topic_AttitudeEuler_t attitude = {0};
	synapse_topic_AttitudeEuler_t attitude_desired = {0};
	synapse_topic_RateTriplet_t rate_desired = {0};
	synapse_topic_RateTriplet_t rate_cmd = {0};
	uint32_t main_loop_latency_us = 0U;
	int64_t now_ms = k_uptime_get();
	int64_t rc_age_ms;

	ARG_UNUSED(argc);
	ARG_UNUSED(argv);

	fc_latest_state(&gyro, &accel, &rc, &status, &attitude, &attitude_desired, &rate_desired,
			&rate_cmd, &main_loop_latency_us);
	rc_age_ms = status.rc_valid ? (now_ms - status.rc_stamp_ms) : -1;

	shell_print(sh,
		    "mode=%s armed=%d imu_ok=%d rc_valid=%d rc_stale=%d arm_switch=%d "
		    "rc_age_ms=%lld lq=%u throttle_us=%ld imu_to_motor_us=%lu",
		    rdd2_flight_mode_name((enum rdd2_flight_mode)status.flight_mode),
		    status.armed ? 1 : 0, status.imu_ok ? 1 : 0, status.rc_valid ? 1 : 0,
		    status.rc_stale ? 1 : 0, status.arm_switch ? 1 : 0, (long long)rc_age_ms,
		    (unsigned int)status.rc_link_quality, (long)status.throttle_us,
		    (unsigned long)main_loop_latency_us);
	fc_print_latency_stats(sh);
	shell_print(sh,
		    "rate_desired roll=%0.3f pitch=%0.3f yaw=%0.3f rate_cmd roll=%0.3f pitch=%0.3f "
		    "yaw=%0.3f",
		    (double)rate_desired.roll, (double)rate_desired.pitch, (double)rate_desired.yaw,
		    (double)rate_cmd.roll, (double)rate_cmd.pitch, (double)rate_cmd.yaw);
	shell_print(sh,
		    "attitude roll=%0.3f pitch=%0.3f yaw=%0.3f attitude_desired roll=%0.3f "
		    "pitch=%0.3f yaw=%0.3f",
		    (double)attitude.roll, (double)attitude.pitch, (double)attitude.yaw,
		    (double)attitude_desired.roll, (double)attitude_desired.pitch,
		    (double)attitude_desired.yaw);

	return 0;
}

static int cmd_fc_gyro(const struct shell *sh, size_t argc, char **argv)
{
	synapse_topic_Vec3f_t gyro = {0};
	synapse_topic_Vec3f_t accel = {0};
	synapse_topic_RcChannels16_t rc = {0};
	synapse_topic_ControlStatus_t status = {0};
	synapse_topic_AttitudeEuler_t attitude = {0};
	synapse_topic_AttitudeEuler_t attitude_desired = {0};
	synapse_topic_RateTriplet_t rate_desired = {0};
	synapse_topic_RateTriplet_t rate_cmd = {0};

	ARG_UNUSED(argc);
	ARG_UNUSED(argv);

	fc_latest_state(&gyro, &accel, &rc, &status, &attitude, &attitude_desired, &rate_desired,
			&rate_cmd, NULL);

	shell_print(sh, "gyro_rad_s x=%0.5f y=%0.5f z=%0.5f", (double)gyro.x, (double)gyro.y,
		    (double)gyro.z);
	shell_print(sh, "accel_m_s2 x=%0.5f y=%0.5f z=%0.5f", (double)accel.x, (double)accel.y,
		    (double)accel.z);

	return 0;
}

static int cmd_fc_rc(const struct shell *sh, size_t argc, char **argv)
{
	synapse_topic_Vec3f_t gyro = {0};
	synapse_topic_Vec3f_t accel = {0};
	synapse_topic_RcChannels16_t rc = {0};
	synapse_topic_ControlStatus_t status = {0};
	synapse_topic_AttitudeEuler_t attitude = {0};
	synapse_topic_AttitudeEuler_t attitude_desired = {0};
	synapse_topic_RateTriplet_t rate_desired = {0};
	synapse_topic_RateTriplet_t rate_cmd = {0};

	ARG_UNUSED(argc);
	ARG_UNUSED(argv);

	fc_latest_state(&gyro, &accel, &rc, &status, &attitude, &attitude_desired, &rate_desired,
			&rate_cmd, NULL);
	fc_latest_rc(&rc);

	shell_print(sh, "rc us ch0=%ld ch1=%ld ch2=%ld ch3=%ld ch4=%ld ch5=%ld ch6=%ld ch7=%ld",
		    (long)rc.ch0, (long)rc.ch1, (long)rc.ch2, (long)rc.ch3, (long)rc.ch4,
		    (long)rc.ch5, (long)rc.ch6, (long)rc.ch7);

	return 0;
}

SHELL_STATIC_SUBCMD_SET_CREATE(
	sub_fc, SHELL_CMD(status, NULL, "show latest flight-control state", cmd_fc_status),
	SHELL_CMD(gyro, NULL, "show latest gyro and accel sample", cmd_fc_gyro),
	SHELL_CMD(rc, NULL, "show latest RC channel sample", cmd_fc_rc), SHELL_SUBCMD_SET_END);
SHELL_CMD_REGISTER(fc, &sub_fc, "flight-control debug commands", NULL);
```

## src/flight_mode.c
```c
/*
 * SPDX-License-Identifier: Apache-2.0
 */

#include "flight_mode.h"

enum rdd2_flight_mode rdd2_flight_mode_from_rc(const synapse_topic_RcChannels16_t *rc)
{
	const int32_t *channels;

	if (rc == NULL) {
		return RDD2_FLIGHT_MODE_ACRO;
	}

	channels = rdd2_topic_rc_channels_data_const(rc);
	if (channels[RDD2_FLIGHT_MODE_CHANNEL_INDEX] >= RDD2_FLIGHT_MODE_SWITCH_US) {
		return RDD2_FLIGHT_MODE_AUTO_LEVEL;
	}

	return RDD2_FLIGHT_MODE_ACRO;
}

const char *rdd2_flight_mode_name(enum rdd2_flight_mode mode)
{
	switch (mode) {
	case RDD2_FLIGHT_MODE_ACRO:
		return "ACRO";
	case RDD2_FLIGHT_MODE_AUTO_LEVEL:
		return "AUTO_LEVEL";
	default:
		return "UNKNOWN";
	}
}
```

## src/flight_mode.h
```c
#ifndef RDD2_FLIGHT_MODE_H_
#define RDD2_FLIGHT_MODE_H_

#include <stdint.h>

#include "topic_flatbuffer.h"

#define RDD2_FLIGHT_MODE_CHANNEL_INDEX 5
#define RDD2_FLIGHT_MODE_SWITCH_US     1500

enum rdd2_flight_mode {
	RDD2_FLIGHT_MODE_ACRO = 0,
	RDD2_FLIGHT_MODE_AUTO_LEVEL = 1,
};

enum rdd2_flight_mode rdd2_flight_mode_from_rc(const synapse_topic_RcChannels16_t *rc);
const char *rdd2_flight_mode_name(enum rdd2_flight_mode mode);

#endif
```

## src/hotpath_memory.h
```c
#ifndef RDD2_HOTPATH_MEMORY_H_
#define RDD2_HOTPATH_MEMORY_H_

#include <zephyr/devicetree.h>

#if defined(CONFIG_BOARD_MR_VMU_TROPIC_MIMXRT1064) && DT_HAS_CHOSEN(zephyr_dtcm) &&                \
	DT_NODE_HAS_STATUS_OKAY(DT_CHOSEN(zephyr_dtcm))
#include <zephyr/linker/section_tags.h>
#define RDD2_HOTPATH_DTCM_BSS __dtcm_bss_section
#else
#define RDD2_HOTPATH_DTCM_BSS
#endif

#endif
```

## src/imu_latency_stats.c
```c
/*
 * SPDX-License-Identifier: Apache-2.0
 */

#include "imu_latency_stats.h"
#include "hotpath_memory.h"

#include <math.h>
#include <string.h>

struct rdd2_imu_latency_stats_state {
	uint32_t sequence;
	struct rdd2_imu_latency_stats_snapshot snapshot;
	uint32_t last_us;
	uint32_t min_us;
	uint32_t max_us;
	uint64_t sample_count;
	double mean_us;
	double m2_us2;
};

static RDD2_HOTPATH_DTCM_BSS struct rdd2_imu_latency_stats_state g_rdd2_imu_latency_stats;

static void rdd2_imu_latency_stats_publish(const struct rdd2_imu_latency_stats_snapshot *snapshot)
{
	__atomic_add_fetch(&g_rdd2_imu_latency_stats.sequence, 1U, __ATOMIC_RELAXED);
	__atomic_thread_fence(__ATOMIC_RELEASE);
	g_rdd2_imu_latency_stats.snapshot = *snapshot;
	__atomic_thread_fence(__ATOMIC_RELEASE);
	__atomic_add_fetch(&g_rdd2_imu_latency_stats.sequence, 1U, __ATOMIC_RELAXED);
}

void rdd2_imu_latency_stats_reset(void)
{
	memset(&g_rdd2_imu_latency_stats, 0, sizeof(g_rdd2_imu_latency_stats));
}

void rdd2_imu_latency_stats_update(uint32_t latency_us)
{
	struct rdd2_imu_latency_stats_snapshot snapshot;
	double delta;
	double delta2;
	double variance_us2;

	if (latency_us == 0U) {
		return;
	}

	g_rdd2_imu_latency_stats.sample_count++;
	g_rdd2_imu_latency_stats.last_us = latency_us;

	if (g_rdd2_imu_latency_stats.sample_count == 1U) {
		g_rdd2_imu_latency_stats.min_us = latency_us;
		g_rdd2_imu_latency_stats.max_us = latency_us;
		g_rdd2_imu_latency_stats.mean_us = (double)latency_us;
		g_rdd2_imu_latency_stats.m2_us2 = 0.0;
	} else {
		if (latency_us < g_rdd2_imu_latency_stats.min_us) {
			g_rdd2_imu_latency_stats.min_us = latency_us;
		}
		if (latency_us > g_rdd2_imu_latency_stats.max_us) {
			g_rdd2_imu_latency_stats.max_us = latency_us;
		}

		delta = (double)latency_us - g_rdd2_imu_latency_stats.mean_us;
		g_rdd2_imu_latency_stats.mean_us +=
			delta / (double)g_rdd2_imu_latency_stats.sample_count;
		delta2 = (double)latency_us - g_rdd2_imu_latency_stats.mean_us;
		g_rdd2_imu_latency_stats.m2_us2 += delta * delta2;
	}

	variance_us2 = 0.0;
	if (g_rdd2_imu_latency_stats.sample_count > 1U) {
		variance_us2 = g_rdd2_imu_latency_stats.m2_us2 /
			       (double)g_rdd2_imu_latency_stats.sample_count;
	}

	snapshot = (struct rdd2_imu_latency_stats_snapshot){
		.last_us = g_rdd2_imu_latency_stats.last_us,
		.min_us = g_rdd2_imu_latency_stats.min_us,
		.max_us = g_rdd2_imu_latency_stats.max_us,
		.mean_us = (float)g_rdd2_imu_latency_stats.mean_us,
		.stddev_us = (float)sqrt(variance_us2),
		.sample_count = g_rdd2_imu_latency_stats.sample_count,
	};
	rdd2_imu_latency_stats_publish(&snapshot);
}

bool rdd2_imu_latency_stats_get(struct rdd2_imu_latency_stats_snapshot *snapshot)
{
	uint32_t start_sequence;
	uint32_t end_sequence;

	if (snapshot == NULL) {
		return false;
	}

	do {
		start_sequence =
			__atomic_load_n(&g_rdd2_imu_latency_stats.sequence, __ATOMIC_ACQUIRE);
		if ((start_sequence & 1U) != 0U) {
			continue;
		}

		*snapshot = g_rdd2_imu_latency_stats.snapshot;
		__atomic_thread_fence(__ATOMIC_ACQUIRE);
		end_sequence =
			__atomic_load_n(&g_rdd2_imu_latency_stats.sequence, __ATOMIC_RELAXED);
	} while (start_sequence != end_sequence || (end_sequence & 1U) != 0U);

	return snapshot->sample_count != 0U;
}
```

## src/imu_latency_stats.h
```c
#ifndef RDD2_IMU_LATENCY_STATS_H_
#define RDD2_IMU_LATENCY_STATS_H_

#include <stdbool.h>
#include <stdint.h>

struct rdd2_imu_latency_stats_snapshot {
	uint32_t last_us;
	uint32_t min_us;
	uint32_t max_us;
	float mean_us;
	float stddev_us;
	uint64_t sample_count;
};

void rdd2_imu_latency_stats_reset(void);
void rdd2_imu_latency_stats_update(uint32_t latency_us);
bool rdd2_imu_latency_stats_get(struct rdd2_imu_latency_stats_snapshot *snapshot);

#endif
```
